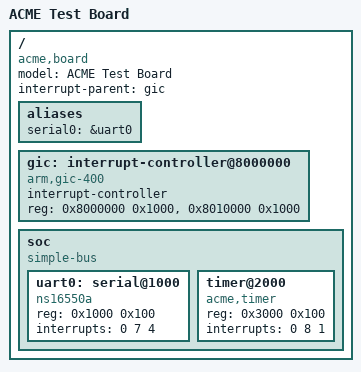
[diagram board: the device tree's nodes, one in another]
/dts-v1/;

/* Test board for devicetree-mcp: a GIC, a UART behind a translating bus,
 * and one deliberate mistake (timer@2000 whose reg says 0x3000). */

/ {
	#address-cells = <1>;
	#size-cells = <1>;
	compatible = "acme,board";
	model = "ACME Test Board";
	interrupt-parent = <&gic>;

	aliases {
		serial0 = &uart0;
	};

	gic: interrupt-controller@8000000 {
		compatible = "arm,gic-400";
		interrupt-controller;
		#interrupt-cells = <3>;
		reg = <0x8000000 0x1000>, <0x8010000 0x1000>;
	};

	soc {
		compatible = "simple-bus";
		#address-cells = <1>;
		#size-cells = <1>;
		ranges = <0x0 0x40000000 0x100000>;

		uart0: serial@1000 {
			compatible = "ns16550a";
			reg = <0x1000 0x100>;
			interrupts = <0 7 4>;
		};

		timer@2000 {
			compatible = "acme,timer";
			reg = <0x3000 0x100>;
			interrupts = <0 8 1>;
		};
	};
};
